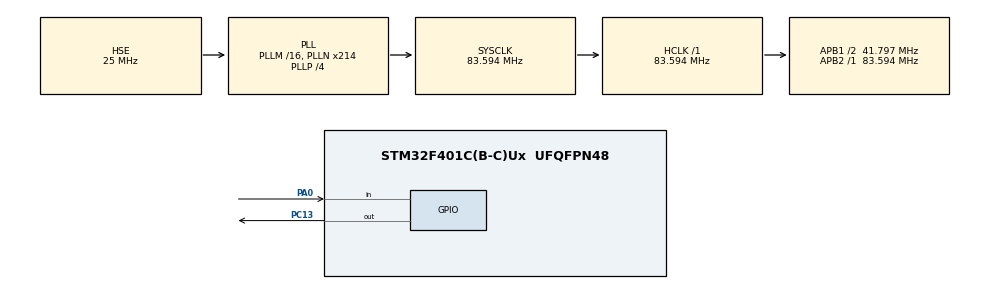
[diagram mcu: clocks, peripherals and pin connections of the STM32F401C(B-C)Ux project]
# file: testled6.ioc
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Mcu.Family=STM32F4
Mcu.Name=STM32F401C(B-C)Ux
Mcu.Package=UFQFPN48
NVIC.PriorityGroup=NVIC_PRIORITYGROUP_4
PA0-WKUP.Signal=GPIO_Input
PA13.Mode=Trace_Asynchronous_SW
PA13.Signal=SYS_JTMS-SWDIO
PA14.Mode=Trace_Asynchronous_SW
PA14.Signal=SYS_JTCK-SWCLK
PB3.Mode=Trace_Asynchronous_SW
PB3.Signal=SYS_JTDO-SWO
PC13-ANTI_TAMP.Signal=GPIO_Output
PC14-OSC32_IN.Mode=LSE-External-Oscillator
PC14-OSC32_IN.Signal=RCC_OSC32_IN
PC15-OSC32_OUT.Mode=LSE-External-Oscillator
PC15-OSC32_OUT.Signal=RCC_OSC32_OUT
PH0\ -\ OSC_IN.Mode=HSE-External-Oscillator
PH0\ -\ OSC_IN.Signal=RCC_OSC_IN
PH1\ -\ OSC_OUT.Mode=HSE-External-Oscillator
PH1\ -\ OSC_OUT.Signal=RCC_OSC_OUT
ProjectManager.HeapSize=0x200
ProjectManager.StackSize=0x400
ProjectManager.TargetToolchain=STM32CubeIDE
RCC.48MHZClocksFreq_Value=83593750
RCC.AHBFreq_Value=83593750
RCC.APB1CLKDivider=RCC_HCLK_DIV2
RCC.APB1Freq_Value=41796875
RCC.APB1TimFreq_Value=83593750
RCC.APB2Freq_Value=83593750
RCC.APB2TimFreq_Value=83593750
RCC.CortexFreq_Value=83593750
RCC.EnbaleCSS=true
RCC.HCLKFreq_Value=83593750
RCC.HSE_VALUE=25000000
RCC.HSI_VALUE=16000000
RCC.PLLN=214
RCC.PLLP=RCC_PLLP_DIV4
RCC.PLLSourceVirtual=RCC_PLLSOURCE_HSE
RCC.SYSCLKFreq_VALUE=83593750
RCC.SYSCLKSource=RCC_SYSCLKSOURCE_PLLCLK
RCC.VCOOutputFreq_Value=334375000
board=custom

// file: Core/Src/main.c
/* USER CODE BEGIN Header */
/**
  ******************************************************************************
  * @file           : main.c
  * @brief          : Main program body
  ******************************************************************************
  * @attention
  *
  * Copyright (c) 2026 STMicroelectronics.
  * All rights reserved.
  *
  * This software is licensed under terms that can be found in the LICENSE file
  * in the root directory of this software component.
  * If no LICENSE file comes with this software, it is provided AS-IS.
  *
  ******************************************************************************
  */
/* USER CODE END Header */
#include "main.h"

/* USER CODE BEGIN Includes */
#include "core_cm4.h"
/* USER CODE END Includes */

/* USER CODE BEGIN PV */
/* Переменные для обработки кнопки и PWM */
volatile uint8_t led_pwm_active = 0;    /* Флаг активного PWM режима: 0 - выкл, 1 - вкл */
uint8_t pwm_duty = 0;                   /* Текущий duty cycle PWM (0-100) */
uint8_t pwm_direction = 0;              /* Направление изменения PWM: 0 - рост, 1 - спад */
volatile uint32_t button_press_time = 0; /* Время нажатия кнопки (для детекции длительного нажатия) */
/* USER CODE END PV */

void SystemClock_Config(void);
static void MX_GPIO_Init(void);

/* USER CODE BEGIN 0 */

/* Задержка в микросекундах для PWM */
static void Delay_us(uint32_t us)
{
  uint32_t start = DWT->CYCCNT;
  uint32_t freq = HAL_RCC_GetHCLKFreq() / 1000000;  /* Частота в МГц */
  while ((DWT->CYCCNT - start) < (us * freq));
}

/* Функция получения текущего уровня RDP */
static uint8_t Get_RDP_Level(void)
{
  FLASH_OBProgramInitTypeDef FLASH_OBInitStruct;

  HAL_FLASH_Unlock();
  HAL_FLASH_OB_Unlock();

  HAL_FLASHEx_OBGetConfig(&FLASH_OBInitStruct);

  HAL_FLASH_OB_Lock();
  HAL_FLASH_Lock();

  return FLASH_OBInitStruct.RDPLevel;
}

/* Функция моргания светодиодом */
static void Blink_LED(uint32_t count)
{
  for (uint32_t i = 0; i < count; i++)
  {
    HAL_GPIO_WritePin(GPIOC, GPIO_PIN_13, GPIO_PIN_RESET);
    HAL_Delay(100);
    HAL_GPIO_WritePin(GPIOC, GPIO_PIN_13, GPIO_PIN_SET);
    HAL_Delay(100);
  }
}

/* Функция установки RDP уровня */
static void Set_RDP(uint8_t level)
{
  FLASH_OBProgramInitTypeDef FLASH_OBInitStruct;

  /* Разблокировка Flash и Option Bytes */
  HAL_FLASH_Unlock();
  HAL_FLASH_OB_Unlock();

  /* Чтение текущей конфигурации Option Bytes */
  HAL_FLASHEx_OBGetConfig(&FLASH_OBInitStruct);

  /* Настройка RDP уровня */
  FLASH_OBInitStruct.OptionType = OPTIONBYTE_RDP;
  FLASH_OBInitStruct.RDPLevel = (level == 1) ? OB_RDP_LEVEL_1 : OB_RDP_LEVEL_0;

  /* Программирование Option Bytes */
  if (HAL_FLASHEx_OBProgram(&FLASH_OBInitStruct) != HAL_OK)
  {
    /* Ошибка программирования */
    Error_Handler();
  }

  /* Запуск изменения Option Bytes */
  HAL_FLASH_OB_Launch();

  /* Блокировка обратно */
  HAL_FLASH_OB_Lock();
  HAL_FLASH_Lock();
}

/* Функция программного PWM для светодиода
 * Светодиод на PC13 активный низкий (0 = горит, 1 = выкл)
 */
static void PWM_LED(uint8_t duty)
{
  /* Светодиод ГОРИТ на duty% периода (низкий уровень) */
  HAL_GPIO_WritePin(GPIOC, GPIO_PIN_13, GPIO_PIN_RESET);
  Delay_us(duty * 10);  /* 10 мкс на 1% duty cycle */

  /* Светодиод ВЫКЛЮЧЕН на (100-duty)% периода (высокий уровень) */
  HAL_GPIO_WritePin(GPIOC, GPIO_PIN_13, GPIO_PIN_SET);
  Delay_us((100 - duty) * 10);
}

/* Функция плавного изменения яркости */
static void Update_PWM(void)
{
  if (pwm_direction == 0)
  {
    pwm_duty++;
    if (pwm_duty >= 100)
    {
      pwm_duty = 100;
      pwm_direction = 1;  /* Меняем направление на спад */
    }
  }
  else
  {
    pwm_duty--;
    if (pwm_duty == 0)
    {
      pwm_duty = 0;
      pwm_direction = 0;  /* Меняем направление на рост */
    }
  }
}

/* USER CODE END 0 */

int main(void)
{

  /* MCU Configuration--------------------------------------------------------*/

  /* Reset of all peripherals, Initializes the Flash interface and the Systick. */
  HAL_Init();

  /* Configure the system clock */
  SystemClock_Config();

  /* Initialize all configured peripherals */
  MX_GPIO_Init();

  /* USER CODE BEGIN 2 */
  /* Инициализация DWT для задержек в микросекундах */
  CoreDebug->DEMCR |= CoreDebug_DEMCR_TRCENA_Msk;
  DWT->CYCCNT = 0;
  DWT->CTRL |= DWT_CTRL_CYCCNTENA_Msk;

  /* Инициализация переменных PWM - по умолчанию светодиод выключен */
  led_pwm_active = 0;
  pwm_duty = 0;
  pwm_direction = 0;
  button_press_time = 0;

  /* Выключаем светодиод изначально (активный низкий - SET = выкл) */
  HAL_GPIO_WritePin(GPIOC, GPIO_PIN_13, GPIO_PIN_SET);
  /* USER CODE END 2 */

  /* Infinite loop */
  /* USER CODE BEGIN WHILE */

  while (1)
  {
    /* Проверка нажатия кнопки PA0 (активный низкий уровень) */
    if (HAL_GPIO_ReadPin(GPIOA, GPIO_PIN_0) == GPIO_PIN_RESET && button_press_time == 0)
    {
      /* Запоминаем время нажатия */
      button_press_time = HAL_GetTick();
    }
    /* Отпускание кнопки */
    else if (HAL_GPIO_ReadPin(GPIOA, GPIO_PIN_0) == GPIO_PIN_SET && button_press_time != 0)
    {
      /* Вычисляем длительность нажатия */
      uint32_t press_duration = HAL_GetTick() - button_press_time;
      button_press_time = 0;

      /* Проверяем, длительное ли это нажатие (>= 2 секунды) */
      if (press_duration >= 2000)
      {
        /* Длительное нажатие: моргаем 3 раза и переключаем RDP */
        Blink_LED(3);
        uint8_t current_rdp = Get_RDP_Level();
        if (current_rdp == OB_RDP_LEVEL_1)
        {
          /* RDP включен, выключаем (Level 0) - произойдет сброс и очистка */
          Set_RDP(0);
          /* Код после этой точки не должен выполняться из-за сброса */
        }
        else
        {
          /* RDP выключен, включаем (Level 1) */
          Set_RDP(1);
          /* Код продолжает работать, RDP активен */
        }
      }
      else
      {
        /* Короткое нажатие: переключаем режим PWM */
        led_pwm_active = !led_pwm_active;

        /* При включении сбрасываем параметры PWM */
        if (led_pwm_active)
        {
          pwm_duty = 0;
          pwm_direction = 0;
        }
        else
        {
          /* При выключении гасим светодиод (активный низкий - SET = выкл) */
          HAL_GPIO_WritePin(GPIOC, GPIO_PIN_13, GPIO_PIN_SET);
        }
      }
    }

    if (led_pwm_active)
    {
      /* Режим плавного PWM: зажигаем и гасим светодиод */
      PWM_LED(pwm_duty);
      Update_PWM();
    }
    /* Если led_pwm_active == 0, светодиод выключен */
  }
  /* USER CODE END 3 */
}

void SystemClock_Config(void)
{
  RCC_OscInitTypeDef RCC_OscInitStruct = {0};
  RCC_ClkInitTypeDef RCC_ClkInitStruct = {0};

  /** Configure the main internal regulator output voltage
  */
  __HAL_RCC_PWR_CLK_ENABLE();
  __HAL_PWR_VOLTAGESCALING_CONFIG(PWR_REGULATOR_VOLTAGE_SCALE2);

  /** Initializes the RCC Oscillators according to the specified parameters
  * in the RCC_OscInitTypeDef structure.
  */
  RCC_OscInitStruct.OscillatorType = RCC_OSCILLATORTYPE_HSE;
  RCC_OscInitStruct.HSEState = RCC_HSE_ON;
  RCC_OscInitStruct.PLL.PLLState = RCC_PLL_ON;
  RCC_OscInitStruct.PLL.PLLSource = RCC_PLLSOURCE_HSE;
  RCC_OscInitStruct.PLL.PLLM = 16;
  RCC_OscInitStruct.PLL.PLLN = 214;
  RCC_OscInitStruct.PLL.PLLP = RCC_PLLP_DIV4;
  RCC_OscInitStruct.PLL.PLLQ = 4;
  if (HAL_RCC_OscConfig(&RCC_OscInitStruct) != HAL_OK)
  {
    Error_Handler();
  }

  /** Initializes the CPU, AHB and APB buses clocks
  */
  RCC_ClkInitStruct.ClockType = RCC_CLOCKTYPE_HCLK|RCC_CLOCKTYPE_SYSCLK
                              |RCC_CLOCKTYPE_PCLK1|RCC_CLOCKTYPE_PCLK2;
  RCC_ClkInitStruct.SYSCLKSource = RCC_SYSCLKSOURCE_PLLCLK;
  RCC_ClkInitStruct.AHBCLKDivider = RCC_SYSCLK_DIV1;
  RCC_ClkInitStruct.APB1CLKDivider = RCC_HCLK_DIV2;
  RCC_ClkInitStruct.APB2CLKDivider = RCC_HCLK_DIV1;

  if (HAL_RCC_ClockConfig(&RCC_ClkInitStruct, FLASH_LATENCY_2) != HAL_OK)
  {
    Error_Handler();
  }

  /** Enables the Clock Security System
  */
  HAL_RCC_EnableCSS();
}

static void MX_GPIO_Init(void)
{
  GPIO_InitTypeDef GPIO_InitStruct = {0};

  /* GPIO Ports Clock Enable */
  __HAL_RCC_GPIOC_CLK_ENABLE();
  __HAL_RCC_GPIOH_CLK_ENABLE();
  __HAL_RCC_GPIOA_CLK_ENABLE();
  __HAL_RCC_GPIOB_CLK_ENABLE();

  /*Configure GPIO pin Output Level */
  HAL_GPIO_WritePin(GPIOC, GPIO_PIN_13, GPIO_PIN_SET);

  /*Configure GPIO pin : PC13 */
  GPIO_InitStruct.Pin = GPIO_PIN_13;
  GPIO_InitStruct.Mode = GPIO_MODE_OUTPUT_PP;
  GPIO_InitStruct.Pull = GPIO_NOPULL;
  GPIO_InitStruct.Speed = GPIO_SPEED_FREQ_LOW;
  HAL_GPIO_Init(GPIOC, &GPIO_InitStruct);

  /*Configure GPIO pin : PA0 */
  GPIO_InitStruct.Pin = GPIO_PIN_0;
  GPIO_InitStruct.Mode = GPIO_MODE_INPUT;
  GPIO_InitStruct.Pull = GPIO_NOPULL;
  HAL_GPIO_Init(GPIOA, &GPIO_InitStruct);

  /* USER CODE BEGIN MX_GPIO_Init_2 */
  /* Добавляем подтяжку для кнопки PA0 (кнопка на GND - нужна pull-up) */
  GPIO_InitStruct.Pin = GPIO_PIN_0;
  GPIO_InitStruct.Mode = GPIO_MODE_INPUT;
  GPIO_InitStruct.Pull = GPIO_PULLUP;
  HAL_GPIO_Init(GPIOA, &GPIO_InitStruct);
  /* USER CODE END MX_GPIO_Init_2 */
}

void Error_Handler(void)
{
  __disable_irq();
  while (1)
  {
  }
}
